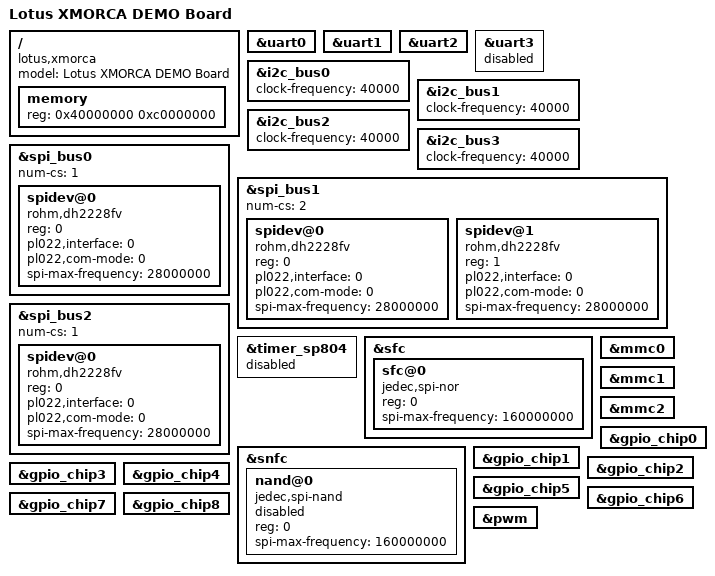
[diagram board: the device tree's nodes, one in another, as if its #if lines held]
// SPDX-License-Identifier: GPL-2.0

/dts-v1/;
#include "xmorca.dtsi"

/ {
	model = "Lotus XMORCA DEMO Board";
	compatible = "lotus,xmorca";

	memory {
		device_type = "memory";
		reg = <0x40000000 0xc0000000>;
	};
};

&uart0 {
	status = "ok";
};

&uart1 {
	status = "ok";
};

&uart2 {
	status = "ok";
};

&uart3 {
	status = "disabled";
};


&i2c_bus0 {
	status = "ok";
#ifdef CONFIG_FPGA_SUPPORT
	clock-frequency = <40000>;
#else
	clock-frequency = <100000>;
#endif
};

&i2c_bus1 {
	status = "ok";
#ifdef CONFIG_FPGA_SUPPORT
	clock-frequency = <40000>;
#else
	clock-frequency = <100000>;
#endif
};

&i2c_bus2 {
	status = "ok";
#ifdef CONFIG_FPGA_SUPPORT
	clock-frequency = <40000>;
#else
	clock-frequency = <100000>;
#endif
};

&i2c_bus3 {
	status = "ok";
#ifdef CONFIG_FPGA_SUPPORT
	clock-frequency = <40000>;
#else
	clock-frequency = <100000>;
#endif
};

&spi_bus0{
	status = "ok";
	num-cs = <1>;

	spidev@0 {
		compatible = "rohm,dh2228fv";
		reg = <0>;
		pl022,interface = <0>;
		pl022,com-mode = <0>;
#ifdef CONFIG_FPGA_SUPPORT
		spi-max-frequency = <28000000>;
#else
		spi-max-frequency = <50000000>;
#endif
	};
};

&spi_bus1{
	status = "ok";
	num-cs = <2>;

	spidev@0 {
		compatible = "rohm,dh2228fv";
		reg = <0>;
		pl022,interface = <0>;
		pl022,com-mode = <0>;
#ifdef CONFIG_FPGA_SUPPORT
		spi-max-frequency = <28000000>;
#else
		spi-max-frequency = <50000000>;
#endif
	};
	spidev@1 {
		compatible = "rohm,dh2228fv";
		reg = <1>;
		pl022,interface = <0>;
		pl022,com-mode = <0>;
#ifdef CONFIG_FPGA_SUPPORT
		spi-max-frequency = <28000000>;
#else
		spi-max-frequency = <50000000>;
#endif
	};
};

&spi_bus2{
	status = "ok";
	num-cs = <1>;

	spidev@0 {
		compatible = "rohm,dh2228fv";
		reg = <0>;
		pl022,interface = <0>;
		pl022,com-mode = <0>;
#ifdef CONFIG_FPGA_SUPPORT
		spi-max-frequency = <28000000>;
#else
		spi-max-frequency = <50000000>;
#endif
	};
};

&timer_sp804 {
	status = "disabled";
};
&sfc {
	sfc@0 {
		compatible = "jedec,spi-nor";
		reg = <0>;
		spi-max-frequency = <160000000>;
	};
};

&snfc {
	nand@0 {
		compatible = "jedec,spi-nand";
		reg = <0>;
		spi-max-frequency = <160000000>;
		status = "disabled";
	};
};

&mmc0 {
	status = "okay";
};

&mmc1 {
	status = "okay";
};

&mmc2 {
	status = "okay";
};

&gpio_chip0 {
	status = "ok";
};

&gpio_chip1 {
	status = "ok";
};

&gpio_chip2 {
	status = "ok";
};

&gpio_chip3 {
	status = "ok";
};

&gpio_chip4 {
	status = "ok";
};

&gpio_chip5 {
	status = "ok";
};

&gpio_chip6 {
	status = "ok";
};

&gpio_chip7 {
	status = "ok";
};

&gpio_chip8 {
	status = "ok";
};

&pwm {
	status = "ok";
};
